# ODS5010 register map
Vendor: OCS; Series: ODS5010; File version: 1.0
CPU: CM0plus r0p0, little endian, MPU, FPU, 4 interrupt priority bits
Registers are 32-bit, read-write, reset 0x0 unless marked. A register's access mark holds for its fields unless they carry their own. Offsets are from the block's base; [hi:lo] are bit positions; {n}, {i} and the like mark numbered series.

## ADC — Analog-to-Digital Converter (ADC) Peripheral
Base 0x40012400; register names take the prefix ADC_
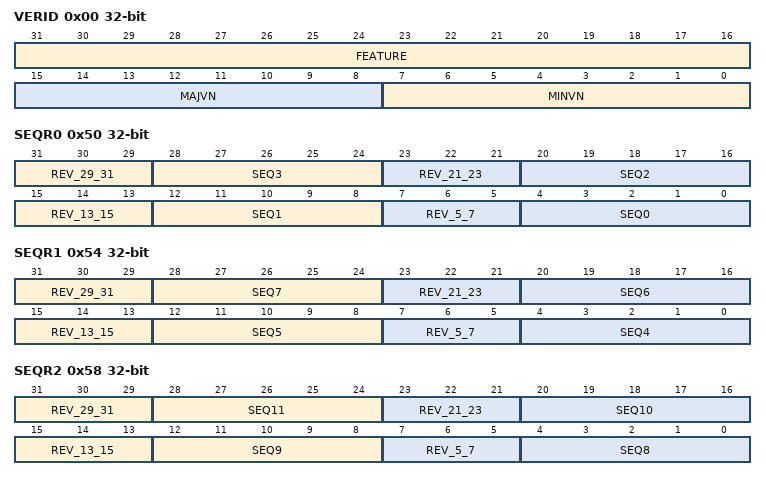
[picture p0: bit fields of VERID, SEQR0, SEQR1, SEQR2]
0x00 VERID — Version Identification Register
  [31:16] FEATURE — Feature Identification
  [15:8] MAJVN — Major Version Number
  [7:0] MINVN — Minor Version Number
{0x4+4i} DATA{i} (i=0..15) — ADC Data Register {i}
0x44 RSV0 — Reserved Register 0
0x48 TGSR — Trigger Status Register
0x4C TGNR — Trigger Number Register
0x50 SEQR0 — Sequence Control Register 0
  [31:29] REV_29_31 — Reserved Bits 29-31
  [8n+4:8n] SEQ{n} (n=0..3) — Sequence Channel {n} Selection
  [23:21] REV_21_23 — Reserved Bits 21-23
  [15:13] REV_13_15 — Reserved Bits 13-15
  [7:5] REV_5_7 — Reserved Bits 5-7
0x54 SEQR1 — Sequence Control Register 1
  [31:29] REV_29_31 — Reserved Bits 29-31
  [8n-28:8n-32] SEQ{n} (n=4..7) — Sequence Channel {n} Selection
  [23:21] REV_21_23 — Reserved Bits 21-23
  [15:13] REV_13_15 — Reserved Bits 13-15
  [7:5] REV_5_7 — Reserved Bits 5-7
0x58 SEQR2 — Sequence Control Register 2
  [31:29] REV_29_31 — Reserved Bits 29-31
  [8n-60:8n-64] SEQ{n} (n=8..11) — Sequence Channel {n} Selection
  [23:21] REV_21_23 — Reserved Bits 21-23
  [15:13] REV_13_15 — Reserved Bits 13-15
  [7:5] REV_5_7 — Reserved Bits 5-7
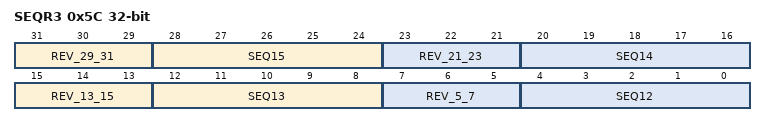
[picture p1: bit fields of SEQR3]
0x5C SEQR3 — Sequence Control Register 3
  [31:29] REV_29_31 — Reserved Bits 29-31
  [8n-92:8n-96] SEQ{n} (n=12..15) — Sequence Channel {n} Selection
  [23:21] REV_21_23 — Reserved Bits 21-23
  [15:13] REV_13_15 — Reserved Bits 13-15
  [7:5] REV_5_7 — Reserved Bits 5-7
0x60 CR — Control Register
0x64 OTR — Over Temperature Register
0x68 TCFG — Timer Configuration Register
0x6C AWTH — Analog Watchdog Threshold High Register
0x70 AWE — Analog Watchdog Enable Register
0x74 IR — Interrupt Request Register
0x78 IE — Interrupt Enable Register
0x7C RSV1 — Reserved Register 1
0x80 CALIB — Calibration Register

## TIM13 — Timer 13 Peripheral
Base 0x40001C00; register names take the prefix TIM13_
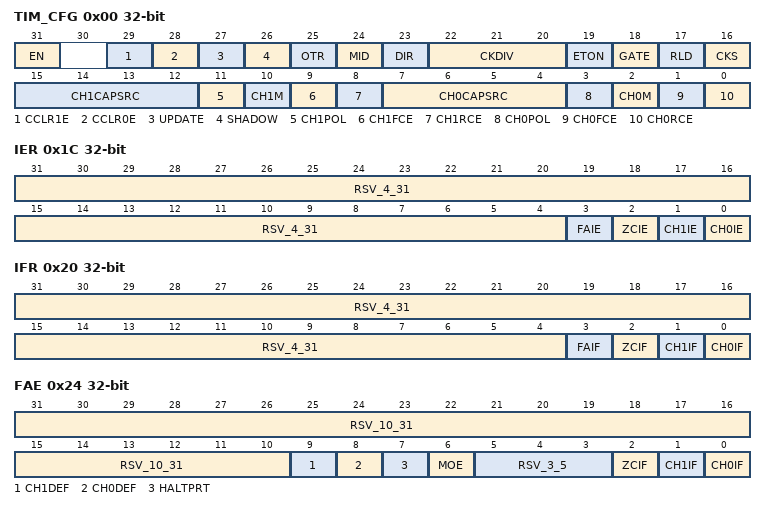
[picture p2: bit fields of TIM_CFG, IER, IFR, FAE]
0x00 TIM_CFG — Timer Configuration Register
  [31] EN — Timer Enable
  [29] CCLR1E — Compare Clear 1 Enable
  [28] CCLR0E — Compare Clear 0 Enable
  [27] UPDATE — Update Enable
  [26] SHADOW — Shadow Register Enable
  [25] OTR — One-Time Reload
  [24] MID — Mode Identification
  [23] DIR — Count Direction
  [22:20] CKDIV — Clock Divider
  [19] ETON — External Trigger Output Enable
  [18] GATE — Gate Control Enable
  [17] RLD — Reload Enable
  [16] CKS — Clock Source Selection
  [15:12] CH1CAPSRC — Channel 1 Capture Source
  [11] CH1POL — Channel 1 Polarity
  [10] CH1M — Channel 1 Mode
  [9] CH1FCE — Channel 1 Falling Edge Capture Enable
  [8] CH1RCE — Channel 1 Rising Edge Capture Enable
  [7:4] CH0CAPSRC — Channel 0 Capture Source
  [3] CH0POL — Channel 0 Polarity
  [2] CH0M — Channel 0 Mode
  [1] CH0FCE — Channel 0 Falling Edge Capture Enable
  [0] CH0RCE — Channel 0 Rising Edge Capture Enable
0x04 TH — Timer High Register
0x08 CNT — Timer Counter Register
0x0C CMP0 — Compare Register 0
0x10 CMP1 — Compare Register 1
0x14 EVTSRC — Event Source Register
0x18 FILT — Filter Register
0x1C IER — Interrupt Enable Register
  [31:4] RSV_4_31 — Reserved Bits 4-31
  [3] FAIE — Function Alarm Interrupt Enable
  [2] ZCIE — Zero Crossing Interrupt Enable
  [1] CH1IE — Channel 1 Interrupt Enable
  [0] CH0IE — Channel 0 Interrupt Enable
0x20 IFR — Interrupt Flag Register
  [31:4] RSV_4_31 — Reserved Bits 4-31
  [3] FAIF — Function Alarm Interrupt Flag
  [2] ZCIF — Zero Crossing Interrupt Flag
  [1] CH1IF — Channel 1 Interrupt Flag
  [0] CH0IF — Channel 0 Interrupt Flag
0x24 FAE — Function Alarm Enable Register
  [31:10] RSV_10_31 — Reserved Bits 10-31
  [9] CH1DEF — Channel 1 Default Value
  [8] CH0DEF — Channel 0 Default Value
  [7] HALTPRT — Halt Protection Enable
  [6] MOE — Master Output Enable
  [5:3] RSV_3_5 — Reserved Bits 3-5
  [2] ZCIF — Zero Crossing Interrupt Flag
  [1] CH1IF — Channel 1 Interrupt Flag
  [0] CH0IF — Channel 0 Interrupt Flag

## TIM14 — Timer 14 Peripheral
Base 0x40002000; register names take the prefix TIM14_
Registers as TIM13.

## TIM15 — Timer 15 Peripheral
Base 0x40014000; register names take the prefix TIM15_
Registers as TIM13.

## TIM16 — Timer 16 Peripheral
Base 0x40014400; register names take the prefix TIM16_
Registers as TIM13.
